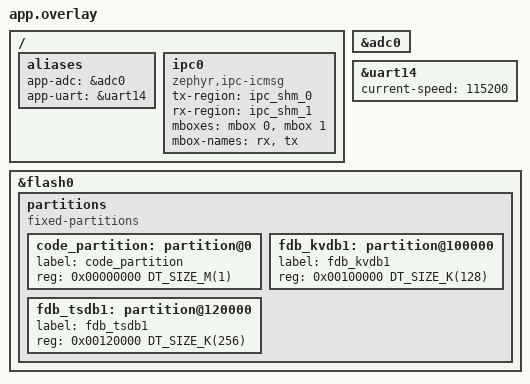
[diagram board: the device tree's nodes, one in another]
&adc0 {
        status = "okay";
};

&uart14 {
        status = "okay";
        current-speed = <115200>;
};

&flash0 {
        partitions {
                compatible = "fixed-partitions";
                #address-cells = <1>;
                #size-cells = <1>;

                code_partition: partition@0 {
                        label = "code_partition";
                        reg = <0x00000000 DT_SIZE_M(1)>;
                };

                fdb_kvdb1: partition@100000 {
                        label = "fdb_kvdb1";
                        reg = <0x00100000 DT_SIZE_K(128)>;
                };

                fdb_tsdb1: partition@120000 {
                        label = "fdb_tsdb1";
                        reg = <0x00120000 DT_SIZE_K(256)>;
                };
        };
};

/ {
    aliases {
        app-adc = &adc0;
        app-uart = &uart14;
    };

    ipc0: ipc0 {
        compatible = "zephyr,ipc-icmsg";
        tx-region = <&ipc_shm_0>;
        rx-region = <&ipc_shm_1>;
        mboxes = <&mbox 0>, <&mbox 1>;
        mbox-names = "rx", "tx";
        status = "okay";
    };
};
